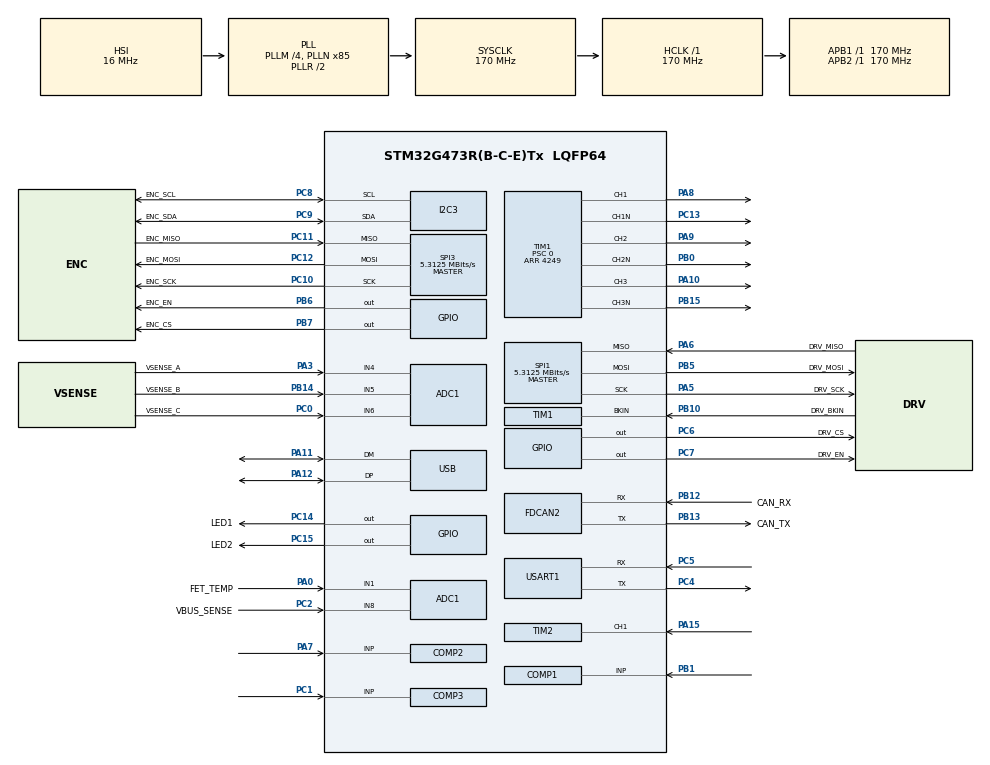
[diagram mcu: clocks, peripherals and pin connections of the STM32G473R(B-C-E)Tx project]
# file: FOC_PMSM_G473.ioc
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ADC1.Channel-0\#ChannelRegularConversion=ADC_CHANNEL_7
ADC1.EOCSelection=ADC_EOC_SEQ_CONV
ADC1.EnableInjectedConversion=ENABLE
ADC1.ExternalTrigConv=ADC_EXTERNALTRIG_T1_TRGO
ADC1.ExternalTrigInjecConv=ADC_EXTERNALTRIGINJEC_T1_TRGO
ADC1.InjNumberOfConversion=1
ADC1.InjectedChannel-1\#ChannelInjectedConversion=ADC_CHANNEL_7
ADC1.InjectedOffsetNumber-1\#ChannelInjectedConversion=ADC_OFFSET_NONE
ADC1.InjectedRank-1\#ChannelInjectedConversion=1
ADC1.InjectedSamplingTime-1\#ChannelInjectedConversion=ADC_SAMPLETIME_6CYCLES_5
ADC1.Mode=ADC_DUALMODE_INJECSIMULT
ADC1.NbrOfConversionFlag=1
ADC1.OffsetNumber-0\#ChannelRegularConversion=ADC_OFFSET_NONE
ADC1.Rank-0\#ChannelRegularConversion=1
ADC1.Rank1_Channel=ADC_CHANNEL_7
ADC1.SamplingTime-0\#ChannelRegularConversion=ADC_SAMPLETIME_6CYCLES_5
ADC1.master=1
ADC2.Channel-0\#ChannelRegularConversion=ADC_CHANNEL_4
ADC2.EnableInjectedConversion=ENABLE
ADC2.EnableInjectedOversampling=DISABLE
ADC2.InjNumberOfConversion=1
ADC2.InjectedChannel-1\#ChannelInjectedConversion=ADC_CHANNEL_4
ADC2.InjectedOffsetNumber-1\#ChannelInjectedConversion=ADC_OFFSET_NONE
ADC2.InjectedRank-1\#ChannelInjectedConversion=1
ADC2.InjectedSamplingTime-1\#ChannelInjectedConversion=ADC_SAMPLETIME_6CYCLES_5
ADC2.Mode=ADC_DUALMODE_INJECSIMULT
ADC2.NbrOfConversionFlag=1
ADC2.OffsetNumber-0\#ChannelRegularConversion=ADC_OFFSET_NONE
ADC2.Rank-0\#ChannelRegularConversion=1
ADC2.Rank1_Channel=ADC_CHANNEL_4
ADC2.SamplingTime-0\#ChannelRegularConversion=ADC_SAMPLETIME_2CYCLES_5
COMP1.Hysteresis=COMP_HYSTERESIS_30MV
FDCAN2.AutoRetransmission=ENABLE
FDCAN2.CalculateBaudRateNominal=499999
FDCAN2.CalculateTimeBitNominal=2000
FDCAN2.CalculateTimeQuantumNominal=117.64705882352942
FDCAN2.NominalPrescaler=20
FDCAN2.NominalSyncJumpWidth=3
FDCAN2.NominalTimeSeg1=13
FDCAN2.NominalTimeSeg2=3 
I2C3.Timing=0x40B285C2
Mcu.Family=STM32G4
Mcu.Name=STM32G473R(B-C-E)Tx
Mcu.Package=LQFP64
NVIC.ADC1_2_IRQn=true\:0\:0\:false\:false\:true\:true\:true\:true
NVIC.PriorityGroup=NVIC_PRIORITYGROUP_4
NVIC.USB_LP_IRQn=true\:0\:0\:false\:false\:true\:false\:true\:true
PA0.GPIO_Label=FET_TEMP
PA0.Mode=IN1-Single-Ended
PA0.Signal=ADC1_IN1
PA10.Signal=S_TIM1_CH3
PA11.Mode=Device
PA11.Signal=USB_DM
PA12.Mode=Device
PA12.Signal=USB_DP
PA13.Mode=Serial_Wire
PA13.Signal=SYS_JTMS-SWDIO
PA14.Mode=Serial_Wire
PA14.Signal=SYS_JTCK-SWCLK
PA15.Signal=S_TIM2_CH1
PA3.GPIO_Label=VSENSE_A
PA3.Mode=IN4-Single-Ended
PA3.Signal=ADC1_IN4
PA5.GPIO_Label=DRV_SCK
PA5.Mode=Full_Duplex_Master
PA5.Signal=SPI1_SCK
PA6.GPIO_Label=DRV_MISO
PA6.Mode=Full_Duplex_Master
PA6.Signal=SPI1_MISO
PA7.Signal=SharedAnalog_PA7
PA8.Signal=S_TIM1_CH1
PA9.Signal=S_TIM1_CH2
PB0.Mode=PWM Generation2 CH2 CH2N
PB0.Signal=TIM1_CH2N
PB1.Signal=SharedAnalog_PB1
PB10.GPIO_Label=DRV_BKIN
PB10.Mode=Activate-Break-Input
PB10.Signal=TIM1_BKIN
PB12.GPIO_Label=CAN_RX
PB12.Mode=FDCAN_Activate
PB12.Signal=FDCAN2_RX
PB13.GPIO_Label=CAN_TX
PB13.Mode=FDCAN_Activate
PB13.Signal=FDCAN2_TX
PB14.GPIO_Label=VSENSE_B
PB14.Mode=IN5-Single-Ended
PB14.Signal=ADC1_IN5
PB15.Mode=PWM Generation3 CH3 CH3N
PB15.Signal=TIM1_CH3N
PB5.GPIO_Label=DRV_MOSI
PB5.Mode=Full_Duplex_Master
PB5.Signal=SPI1_MOSI
PB6.GPIO_Label=ENC_EN
PB6.Signal=GPIO_Output
PB7.GPIO_Label=ENC_CS
PB7.GPIO_Speed=GPIO_SPEED_FREQ_HIGH
PB7.PinState=GPIO_PIN_SET
PB7.Signal=GPIO_Output
PC0.GPIO_Label=VSENSE_C
PC0.Mode=IN6-Single-Ended
PC0.Signal=ADC1_IN6
PC1.Signal=SharedAnalog_PC1
PC10.GPIO_Label=ENC_SCK
PC10.Mode=Full_Duplex_Master
PC10.Signal=SPI3_SCK
PC11.GPIO_Label=ENC_MISO
PC11.Mode=Full_Duplex_Master
PC11.Signal=SPI3_MISO
PC12.GPIO_Label=ENC_MOSI
PC12.Mode=Full_Duplex_Master
PC12.Signal=SPI3_MOSI
PC13.Mode=PWM Generation1 CH1 CH1N
PC13.Signal=TIM1_CH1N
PC14-OSC32_IN.GPIO_Label=LED1
PC14-OSC32_IN.Signal=GPIO_Output
PC15-OSC32_OUT.GPIO_Label=LED2
PC15-OSC32_OUT.Signal=GPIO_Output
PC2.GPIO_Label=VBUS_SENSE
PC2.Mode=IN8-Single-Ended
PC2.Signal=ADC1_IN8
PC4.Mode=Asynchronous
PC4.Signal=USART1_TX
PC5.Mode=Asynchronous
PC5.Signal=USART1_RX
PC6.GPIO_Label=DRV_CS
PC6.GPIO_Speed=GPIO_SPEED_FREQ_HIGH
PC6.PinState=GPIO_PIN_SET
PC6.Signal=GPIO_Output
PC7.GPIO_Label=DRV_EN
PC7.GPIO_Speed=GPIO_SPEED_FREQ_HIGH
PC7.PinState=GPIO_PIN_SET
PC7.Signal=GPIO_Output
PC8.GPIO_Label=ENC_SCL
PC8.Mode=I2C
PC8.Signal=I2C3_SCL
PC9.GPIO_Label=ENC_SDA
PC9.Mode=I2C
PC9.Signal=I2C3_SDA
ProjectManager.HeapSize=0x200
ProjectManager.StackSize=0x400
ProjectManager.TargetToolchain=STM32CubeIDE
RCC.ADC12Freq_Value=170000000
RCC.ADC345Freq_Value=170000000
RCC.AHBFreq_Value=170000000
RCC.APB1Freq_Value=170000000
RCC.APB1TimFreq_Value=170000000
RCC.APB2Freq_Value=170000000
RCC.APB2TimFreq_Value=170000000
RCC.CK48CLockSelection=RCC_USBCLKSOURCE_HSI48
RCC.CortexFreq_Value=170000000
RCC.EXTERNAL_CLOCK_VALUE=12288000
RCC.HCLKFreq_Value=170000000
RCC.HSE_VALUE=8000000
RCC.HSI48_VALUE=48000000
RCC.HSI_VALUE=16000000
RCC.LSE_VALUE=32768
RCC.LockedElements=AHBOutput
RCC.PLLM=RCC_PLLM_DIV4
RCC.PLLN=85
RCC.SYSCLKFreq_VALUE=170000000
RCC.SYSCLKSource=RCC_SYSCLKSOURCE_PLLCLK
RCC.USBFreq_Value=48000000
RCC.VCOOutputFreq_Value=340000000
SH.S_TIM1_CH1.0=TIM1_CH1,PWM Generation1 CH1 CH1N
SH.S_TIM1_CH2.0=TIM1_CH2,PWM Generation2 CH2 CH2N
SH.S_TIM1_CH3.0=TIM1_CH3,PWM Generation3 CH3 CH3N
SH.S_TIM2_CH1.0=TIM2_CH1,Input_Capture1_from_TI1
SH.SharedAnalog_PA7.0=COMP2_INP,INP
SH.SharedAnalog_PA7.1=ADC2_IN4,IN4-Single-Ended
SH.SharedAnalog_PB1.0=COMP1_INP,INP
SH.SharedAnalog_PB1.1=ADC1_IN12,IN12-Single-Ended
SH.SharedAnalog_PC1.0=COMP3_INP,INP
SH.SharedAnalog_PC1.1=ADC1_IN7,IN7-Single-Ended
SPI1.BaudRatePrescaler=SPI_BAUDRATEPRESCALER_32
SPI1.CLKPhase=SPI_PHASE_2EDGE
SPI1.CLKPolarity=SPI_POLARITY_LOW
SPI1.CalculateBaudRate=5.3125 MBits/s
SPI1.DataSize=SPI_DATASIZE_16BIT
SPI1.Direction=SPI_DIRECTION_2LINES
SPI1.Mode=SPI_MODE_MASTER
SPI1.VirtualType=VM_MASTER
SPI3.BaudRatePrescaler=SPI_BAUDRATEPRESCALER_32
SPI3.CLKPhase=SPI_PHASE_2EDGE
SPI3.CLKPolarity=SPI_POLARITY_LOW
SPI3.CalculateBaudRate=5.3125 MBits/s
SPI3.DataSize=SPI_DATASIZE_16BIT
SPI3.Direction=SPI_DIRECTION_2LINES
SPI3.Mode=SPI_MODE_MASTER
SPI3.VirtualType=VM_MASTER
TIM1.AutoReloadPreload=TIM_AUTORELOAD_PRELOAD_ENABLE
TIM1.AutomaticOutput=TIM_AUTOMATICOUTPUT_ENABLE
TIM1.BreakState=TIM_BREAK_DISABLE
TIM1.Channel-PWM\ Generation1\ CH1\ CH1N=TIM_CHANNEL_1
TIM1.Channel-PWM\ Generation2\ CH2\ CH2N=TIM_CHANNEL_2
TIM1.Channel-PWM\ Generation3\ CH3\ CH3N=TIM_CHANNEL_3
TIM1.CounterMode=TIM_COUNTERMODE_CENTERALIGNED1
TIM1.DeadTime=100
TIM1.OffStateIDLEMode=TIM_OSSI_ENABLE
TIM1.OffStateRunMode=TIM_OSSR_ENABLE
TIM1.PeriodNoDither=4249
TIM1.Prescaler=0
TIM1.SourceBRKCOMP1=TIM_BREAKINPUTSOURCE_ENABLE
TIM1.SourceBRKCOMP2=TIM_BREAKINPUTSOURCE_ENABLE
TIM1.SourceBRKCOMP3=TIM_BREAKINPUTSOURCE_ENABLE
TIM1.TIM_MasterOutputTrigger=TIM_TRGO_UPDATE
TIM2.Channel-Input_Capture1_from_TI1=TIM_CHANNEL_1
USART1.VirtualMode-Asynchronous=VM_ASYNC
USB_DEVICE.CLASS_NAME_FS=CDC
USB_DEVICE.VirtualMode=Cdc
USB_DEVICE.VirtualModeFS=Cdc_FS
VP_COMP1_VS_VREFINT.Mode=VREFINT
VP_COMP2_VS_VREFINT.Mode=VREFINT
VP_COMP3_VS_VREFINT.Mode=VREFINT
VP_SYS_VS_DBSignals.Mode=DisableDeadBatterySignals
VP_USB_DEVICE_VS_USB_DEVICE_CDC_FS.Mode=CDC_FS
board=custom

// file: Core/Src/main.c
/* USER CODE BEGIN Header */
/**
 ******************************************************************************
 * @file           : main.c
 * @brief          : Main program body
 ******************************************************************************
 * @attention
 *
 * Copyright (c) 2026 STMicroelectronics.
 * All rights reserved.
 *
 * This software is licensed under terms that can be found in the LICENSE file
 * in the root directory of this software component.
 * If no LICENSE file comes with this software, it is provided AS-IS.
 *
 ******************************************************************************
 */
/* USER CODE END Header */
#include "main.h"
#include "adc.h"
#include "comp.h"
#include "fdcan.h"
#include "gpio.h"
#include "i2c.h"
#include "spi.h"
#include "tim.h"
#include "usart.h"
#include "usb_device.h"

/* USER CODE BEGIN Includes */
#include "app_main.h"
/* USER CODE END Includes */

void SystemClock_Config(void);

int main(void) {

  /* MCU Configuration--------------------------------------------------------*/

  /* Reset of all peripherals, Initializes the Flash interface and the Systick.
   */
  HAL_Init();

  /* Configure the system clock */
  SystemClock_Config();

  /* Initialize all configured peripherals */
  MX_GPIO_Init();
  MX_ADC1_Init();
  MX_COMP1_Init();
  MX_COMP2_Init();
  MX_COMP3_Init();
  MX_TIM1_Init();
  MX_FDCAN2_Init();
  MX_SPI1_Init();
  MX_SPI3_Init();
  MX_USART1_UART_Init();
  MX_I2C3_Init();
  MX_TIM2_Init();
  MX_ADC2_Init();
  MX_USB_Device_Init();
  /* USER CODE BEGIN 2 */
  App_Init();
  /* USER CODE END 2 */

  /* Infinite loop */
  /* USER CODE BEGIN WHILE */
  while (1) {
    App_Loop();
    /* USER CODE END WHILE */

  }
}

void SystemClock_Config(void) {
  RCC_OscInitTypeDef RCC_OscInitStruct = {0};
  RCC_ClkInitTypeDef RCC_ClkInitStruct = {0};

  /** Configure the main internal regulator output voltage
   */
  HAL_PWREx_ControlVoltageScaling(PWR_REGULATOR_VOLTAGE_SCALE1_BOOST);

  /** Initializes the RCC Oscillators according to the specified parameters
   * in the RCC_OscInitTypeDef structure.
   */
  RCC_OscInitStruct.OscillatorType =
      RCC_OSCILLATORTYPE_HSI | RCC_OSCILLATORTYPE_HSI48;
  RCC_OscInitStruct.HSIState = RCC_HSI_ON;
  RCC_OscInitStruct.HSICalibrationValue = RCC_HSICALIBRATION_DEFAULT;
  RCC_OscInitStruct.HSI48State = RCC_HSI48_ON;
  RCC_OscInitStruct.PLL.PLLState = RCC_PLL_ON;
  RCC_OscInitStruct.PLL.PLLSource = RCC_PLLSOURCE_HSI;
  RCC_OscInitStruct.PLL.PLLM = RCC_PLLM_DIV4;
  RCC_OscInitStruct.PLL.PLLN = 85;
  RCC_OscInitStruct.PLL.PLLP = RCC_PLLP_DIV2;
  RCC_OscInitStruct.PLL.PLLQ = RCC_PLLQ_DIV2;
  RCC_OscInitStruct.PLL.PLLR = RCC_PLLR_DIV2;
  if (HAL_RCC_OscConfig(&RCC_OscInitStruct) != HAL_OK) {
    Error_Handler();
  }

  /** Initializes the CPU, AHB and APB buses clocks
   */
  RCC_ClkInitStruct.ClockType = RCC_CLOCKTYPE_HCLK | RCC_CLOCKTYPE_SYSCLK |
                                RCC_CLOCKTYPE_PCLK1 | RCC_CLOCKTYPE_PCLK2;
  RCC_ClkInitStruct.SYSCLKSource = RCC_SYSCLKSOURCE_PLLCLK;
  RCC_ClkInitStruct.AHBCLKDivider = RCC_SYSCLK_DIV1;
  RCC_ClkInitStruct.APB1CLKDivider = RCC_HCLK_DIV1;
  RCC_ClkInitStruct.APB2CLKDivider = RCC_HCLK_DIV1;

  if (HAL_RCC_ClockConfig(&RCC_ClkInitStruct, FLASH_LATENCY_4) != HAL_OK) {
    Error_Handler();
  }
}

void Error_Handler(void) {
  __disable_irq();
  while (1) {
  }
}
#ifdef USE_FULL_ASSERT
/**
 * @brief  Reports the name of the source file and the source line number
 *         where the assert_param error has occurred.
 * @param  file: pointer to the source file name
 * @param  line: assert_param error line source number
 * @retval None
 */
void assert_failed(uint8_t *file, uint32_t line) {
  /* USER CODE BEGIN 6 */
  /* User can add his own implementation to report the file name and line
     number, ex: printf("Wrong parameters value: file %s on line %d\r\n", file,
     line) */
  /* USER CODE END 6 */
}
#endif /* USE_FULL_ASSERT */
